AUTOSAR XML (schema 00044)
package /ComponentTypes
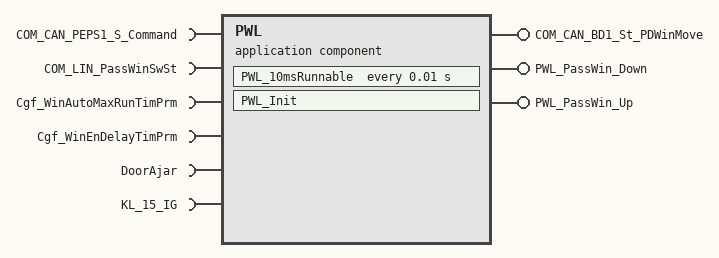
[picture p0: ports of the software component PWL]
  application sw component type PWL
    provide port COM_CAN_BD1_St_PDWinMove: nonqueued-sender-com-spec{data-element=u8_Signal, init-value=0}, provided-interface=COM_CAN_BD1_St_PDWinMove
    provide port PWL_PassWin_Down: nonqueued-sender-com-spec{data-element=u8_Signal, init-value=0}, provided-interface=PWL_PassWin_Down
    provide port PWL_PassWin_Up: nonqueued-sender-com-spec{data-element=u8_Signal, init-value=0}, provided-interface=PWL_PassWin_Up
    6 x require port, all with nonqueued-receiver-com-spec{data-element=u8_Signal, init-value=0}:
      COM_CAN_PEPS1_S_Command: required-interface=COM_CAN_PEPS1_S_Command
      COM_LIN_PassWinSwSt: required-interface=COM_LIN_PassWinSwSt
      Cgf_WinAutoMaxRunTimPrm: required-interface=Cgf_WinAutoMaxRunTimPrm
      Cgf_WinEnDelayTimPrm: required-interface=Cgf_WinEnDelayTimPrm
      DoorAjar: required-interface=DoorAjar
      KL_15_IG: required-interface=KL_15_IG
    behavior PWL_InternalBehavior
      init event PWL_InitEvent: start-on-event=PWL_Init
      timing event TMT_PWL_10msRunnable: start-on-event=PWL_10msRunnable, period=0.01
      runnable PWL_10msRunnable
        data-receive-point-by-arguments:
          6 x access:
            REC_COM_CAN_PEPS1_S_Command_u8_Signal: accessed-variable=COM_CAN_PEPS1_S_Command.u8_Signal
            REC_COM_LIN_PassWinSwSt_u8_Signal: accessed-variable=COM_LIN_PassWinSwSt.u8_Signal
            REC_Cgf_WinAutoMaxRunTimPrm_u8_Signal: accessed-variable=Cgf_WinAutoMaxRunTimPrm.u8_Signal
            REC_Cgf_WinEnDelayTimPrm_u8_Signal: accessed-variable=Cgf_WinEnDelayTimPrm.u8_Signal
            REC_DoorAjar_u8_Signal: accessed-variable=DoorAjar.u8_Signal
            REC_KL_15_IG_u8_Signal: accessed-variable=KL_15_IG.u8_Signal
        data-send-points:
          access SEND_COM_CAN_BD1_St_PDWinMove_u8_Signal: accessed-variable=COM_CAN_BD1_St_PDWinMove.u8_Signal
          access SEND_PWL_PassWin_Down_u8_Signal: accessed-variable=PWL_PassWin_Down.u8_Signal
          access SEND_PWL_PassWin_Up_u8_Signal: accessed-variable=PWL_PassWin_Up.u8_Signal
      runnable PWL_Init
  swc implementation PWL_Implementation: behavior=PWL_InternalBehavior
